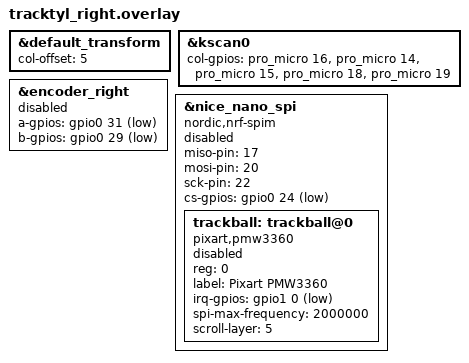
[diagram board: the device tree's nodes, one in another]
#include "tracktyl.dtsi"

&default_transform { // The matrix transform for this board is 5 columns over because the left half is 5 columns wide according to the matrix.
    col-offset = <5>;
};

&kscan0 {
        col-gpios
            = <&pro_micro 16 (GPIO_ACTIVE_HIGH | GPIO_PULL_DOWN)>
            , <&pro_micro 14 (GPIO_ACTIVE_HIGH | GPIO_PULL_DOWN)>
            , <&pro_micro 15 (GPIO_ACTIVE_HIGH | GPIO_PULL_DOWN)>
            , <&pro_micro 18 (GPIO_ACTIVE_HIGH | GPIO_PULL_DOWN)>
            , <&pro_micro 19 (GPIO_ACTIVE_HIGH | GPIO_PULL_DOWN)>
            ;
};

/* Enable the right encoder and define its pins */
&encoder_right {
    status = "disabled";  // disable encoders until further hardware impl
    a-gpios = <&gpio0 31 (GPIO_ACTIVE_LOW | GPIO_PULL_UP)>;
    b-gpios = <&gpio0 29 (GPIO_ACTIVE_LOW | GPIO_PULL_UP)>;
};

&nice_nano_spi {
    /*
        sck -> P0.22 -> left 7
        miso -> P0.17 -> left 5
        cs -> P0.24 -> left 8
        irq -> P1.0 -> left 9
        mosi -> P0.20 -> left 6
        gnd -> left 3, left 4, right 2
        vdd -> right 4
    */
    compatible = "nordic,nrf-spim";
    status = "disabled";
    miso-pin = <17>; // P0.17
    mosi-pin = <20>; // P0.20
    sck-pin = <22>; // P0.22
    cs-gpios = <&gpio0 24 GPIO_ACTIVE_LOW>; // P0.24

    trackball: trackball@0 {
        status = "disabled";
        compatible = "pixart,pmw3360";
        reg = <0>;
        label = "Pixart PMW3360";
        irq-gpios = <&gpio1 0 (GPIO_ACTIVE_LOW | GPIO_PULL_UP)>;
        spi-max-frequency = <2000000>;
        scroll-layer = <5>;
    };
};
